# STM32WB09 register map
File version: 1.0
CPU: CM0+ r0p0, little endian, MPU, no FPU, 2 interrupt priority bits
Registers are 32-bit, read-write, reset 0x0 unless marked. A register's access mark holds for its fields unless they carry their own. Offsets are from the block's base; [hi:lo] are bit positions.

## RADIO
Base 0x60001500
0x00 AA0_DIG_USR reset 0xD6
  [7:0] AA_7_0 — Least significant byte of the Bluetooth LE Access Address code
0x04 AA1_DIG_USR reset 0xBE
  [7:0] AA_15_8 — Next byte of the Bluetooth LE Access Address code.
0x08 AA2_DIG_USR reset 0x89
  [7:0] AA_23_16 — Next byte of the Bluetooth LE Access Address code
0x0C AA3_DIG_USR reset 0x8E
  [7:0] AA_31_24 — Most significant byte of the Bluetooth LE Access Address code.
0x10 DEM_MOD_DIG_USR reset 0x26
  [7:1] CHANNEL_NUM — Index for internal lock up table in which the synthesizer setup is contained.
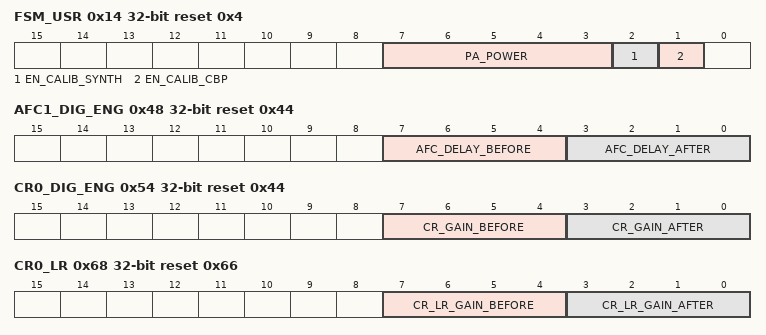
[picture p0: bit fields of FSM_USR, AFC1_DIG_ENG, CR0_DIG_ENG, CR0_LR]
0x14 FSM_USR reset 0x4 — RADIO_FSM_USR register
  [7:3] PA_POWER — PA Power coefficient.
  [2] EN_CALIB_SYNTH — SYNTH calibration enable bit.
  [1] EN_CALIB_CBP — CBP calibration enable bit.
0x18 PHYCTRL_DIG_USR
  [2:0] RXTXPHY — RXTXPHY selection.
0x48 AFC1_DIG_ENG reset 0x44
  [7:4] AFC_DELAY_BEFORE — Set the decay factor of the AFC loop before Access Address detection
  [3:0] AFC_DELAY_AFTER — Set the decay factor of the AFC loop after Access Address detection
0x54 CR0_DIG_ENG reset 0x44
  [7:4] CR_GAIN_BEFORE — Set the gain of the clock recovery loop before Access Address detection to the value
  [3:0] CR_GAIN_AFTER — Set the gain of the clock recovery loop before Access Address detection to the value
0x68 CR0_LR reset 0x66
  [7:4] CR_LR_GAIN_BEFORE — Set the gain of the clock recovery loop before Access Address detection to the value 2^(-CR_LR_GAIN_ BEFORE) when the coded PHY is in use
  [3:0] CR_LR_GAIN_AFTER — Set the gain of the clock recovery loop after Access Address detection to the value 2^(-CR_LR_GAIN_ AFTER) when the coded PHY is in use
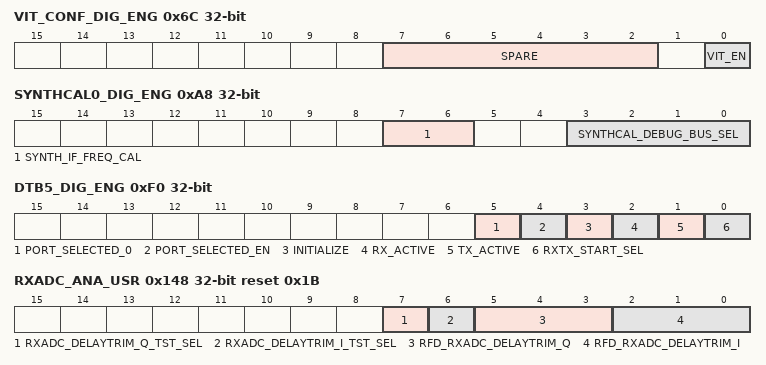
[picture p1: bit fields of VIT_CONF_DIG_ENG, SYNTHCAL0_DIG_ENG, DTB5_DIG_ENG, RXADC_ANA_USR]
0x6C VIT_CONF_DIG_ENG
  [7:2] SPARE
  [0] VIT_EN — Viterbi enable
0x84 LR_PD_THR_DIG_ENG reset 0x50
  [7:0] LR_PD_THR — preamble detect threshold value
0x88 LR_RSSI_THR_DIG_ENG reset 0x1B
  [7:0] LR_RSSI_THR — RSSI or peak threshold value
0x8C LR_AAC_THR_DIG_ENG reset 0x38
  [7:0] LR_AAC_THR — address coded correlation threshold
0xA8 SYNTHCAL0_DIG_ENG
  [7:6] SYNTH_IF_FREQ_CAL — Define the frequency applied on the PLL during calibration phase
  [3:0] SYNTHCAL_DEBUG_BUS_SEL — for Debug purpose
0xF0 DTB5_DIG_ENG
  [5] PORT_SELECTED_0 — force port_selected[0] signal
  [4] PORT_SELECTED_EN — enable port selection
  [3] INITIALIZE — Force INITIALIZE signal (emulate a token request of the IP_BLE)
  [2] RX_ACTIVE — Force RX_ACTIVE signal
  [1] TX_ACTIVE — Force TX_ACTIVE signal
  [0] RXTX_START_SEL — enable the possibility to control some signals by the other register bits instead of system design:
0x148 RXADC_ANA_USR reset 0x1B
  [7] RXADC_DELAYTRIM_Q_TST_SEL — Enable the SW overload on RXADX delay trimming
  [6] RXADC_DELAYTRIM_I_TST_SEL — Enable the SW overload on RXADX delay trimming
  [5:3] RFD_RXADC_DELAYTRIM_Q — ADC loop delay control bits for Q channel to apply when SW overload is enabled
  [2:0] RFD_RXADC_DELAYTRIM_I — ADC loop delay control bits for I channel to apply when SW overload is enabled
0x154 LDO_ANA_ENG
  [0] RFD_RF_REG_BYPASS — RF_REG Bypass mode:
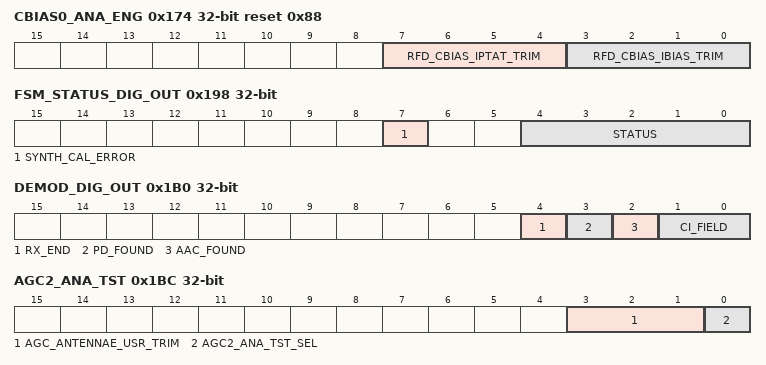
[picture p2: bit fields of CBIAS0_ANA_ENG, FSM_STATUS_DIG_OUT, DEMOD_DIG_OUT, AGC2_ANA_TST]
0x174 CBIAS0_ANA_ENG reset 0x88
  [7:4] RFD_CBIAS_IPTAT_TRIM — overloaded value for cbias current trimming (when CBIAS0_TRIM_TST_SEL = 1)
  [3:0] RFD_CBIAS_IBIAS_TRIM — overloaded value for cbias current trimming (when CBIAS0_TRIM_TST_SEL = 1)
0x178 CBIAS1_ANA_ENG
  [7] CBIAS0_TRIM_TST_SEL — When set, RFD_CBIAS_(IPTAT/IBIAS)_TRIM are used instead of HW trimmings
0x180 SYNTHCAL0_DIG_OUT ro
  [6:0] VCO_CALAMP_OUT_6_0 — VCO CALAMP value
0x184 SYNTHCAL1_DIG_OUT ro reset 0x1
  [3:0] VCO_CALAMP_OUT_10_7 — VCO CALAMP value
0x188 SYNTHCAL2_DIG_OUT ro reset 0x40
  [6:0] VCO_CALFREQ_OUT — VCO CALFREQ value
0x18C SYNTHCAL3_DIG_OUT ro
  [7:0] SYNTHCAL_DEBUG_BUS — Calibration debug bus.
0x190 SYNTHCAL4_DIG_OUT ro reset 0x18
  [5:0] MOD_REF_DAC_WORD_OUT — Calibration word
0x194 SYNTHCAL5_DIG_OUT ro reset 0x7
  [3:0] CBP_CALIB_WORD — CBP Calibration word
0x198 FSM_STATUS_DIG_OUT ro
  [7] SYNTH_CAL_ERROR — PLL calibration error
  [4:0] STATUS — RF FSM state:
0x1A4 RSSI0_DIG_OUT ro reset 0x8
  [7:0] RSSI_MEAS_OUT_7_0 — Measure of the received signal strength.
0x1A8 RSSI1_DIG_OUT ro reset 0x8
  [7:0] RSSI_MEAS_OUT_15_8 — Measure of the received signal strength
0x1AC AGC_DIG_OUT ro
  [3:0] AGC_ATT_OUT — AGC attenuation value
0x1B0 DEMOD_DIG_OUT ro
  [4] RX_END, [3] PD_FOUND, [2] AAC_FOUND, [1:0] CI_FIELD
0x1BC AGC2_ANA_TST
  [3:1] AGC_ANTENNAE_USR_TRIM — the AGC antenna trimming value ( when AGC2_ANA_TST_SEL = 1)
  [0] AGC2_ANA_TST_SEL — Selection:
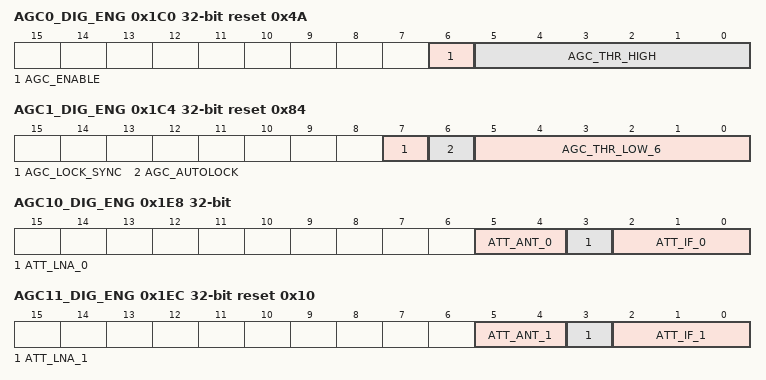
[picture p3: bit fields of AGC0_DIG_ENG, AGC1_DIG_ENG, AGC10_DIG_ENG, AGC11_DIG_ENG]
0x1C0 AGC0_DIG_ENG reset 0x4A
  [6] AGC_ENABLE — Enable AGC
  [5:0] AGC_THR_HIGH — High AGC threshold
0x1C4 AGC1_DIG_ENG reset 0x84
  [7] AGC_LOCK_SYNC — AGC locks when Access Address is detected (recommended)
  [6] AGC_AUTOLOCK — AGC locks when level is steady between high threshold and lock threshold
  [5:0] AGC_THR_LOW_6 — Low threshold for 6dB steps
0x1E8 AGC10_DIG_ENG
  [5:4] ATT_ANT_0 — Attenuation at Antenna Level for the AGC step 0:
  [3] ATT_LNA_0 — Attenuation at LNA Level for the AGC step 0:
  [2:0] ATT_IF_0 — Attenuation at IF Level for the AGC step 0:
0x1EC AGC11_DIG_ENG reset 0x10
  [5:4] ATT_ANT_1 — Attenuation at Antenna Level for the AGC step 1
  [3] ATT_LNA_1 — Attenuation at LNA Level for the AGC step 1
  [2:0] ATT_IF_1 — Attenuation at IF Level for the AGC step 1
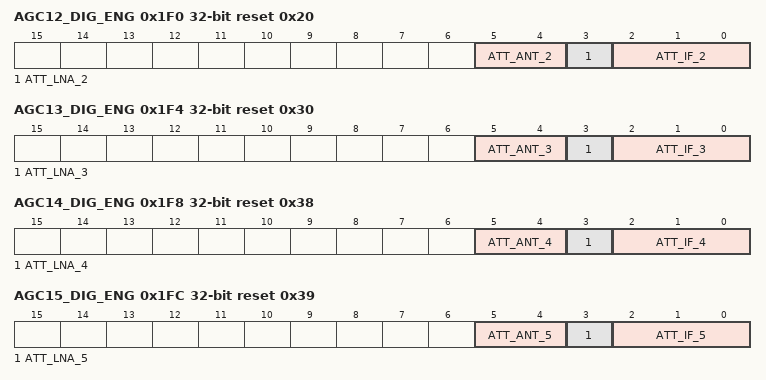
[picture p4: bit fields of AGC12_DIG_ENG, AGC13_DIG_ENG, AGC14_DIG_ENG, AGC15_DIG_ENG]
0x1F0 AGC12_DIG_ENG reset 0x20
  [5:4] ATT_ANT_2 — Attenuation at Antenna Level for the AGC step 2
  [3] ATT_LNA_2 — Attenuation at LNA Level for the AGC step 2
  [2:0] ATT_IF_2 — Attenuation at IF Level for the AGC step 2
0x1F4 AGC13_DIG_ENG reset 0x30
  [5:4] ATT_ANT_3 — Attenuation at Antenna Level for the AGC step 3
  [3] ATT_LNA_3 — Attenuation at LNA Level for the AGC step 3
  [2:0] ATT_IF_3 — Attenuation at IF Level for the AGC step 3
0x1F8 AGC14_DIG_ENG reset 0x38
  [5:4] ATT_ANT_4 — Attenuation at Antenna Level for the AGC step 4
  [3] ATT_LNA_4 — Attenuation at LNA Level for the AGC step 4
  [2:0] ATT_IF_4 — Attenuation at IF Level for the AGC step 4
0x1FC AGC15_DIG_ENG reset 0x39
  [5:4] ATT_ANT_5 — Attenuation at Antenna Level for the AGC step 5
  [3] ATT_LNA_5 — Attenuation at LNA Level for the AGC step 5
  [2:0] ATT_IF_5 — Attenuation at IF Level for the AGC step 5
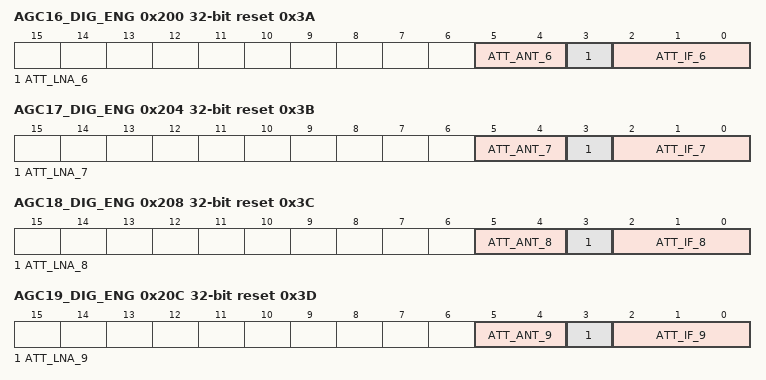
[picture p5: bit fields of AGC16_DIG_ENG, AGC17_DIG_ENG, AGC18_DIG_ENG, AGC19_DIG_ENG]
0x200 AGC16_DIG_ENG reset 0x3A
  [5:4] ATT_ANT_6 — Attenuation at Antenna Level for the AGC step 6
  [3] ATT_LNA_6 — Attenuation at LNA Level for the AGC step 6
  [2:0] ATT_IF_6 — Attenuation at IF Level for the AGC step 6
0x204 AGC17_DIG_ENG reset 0x3B
  [5:4] ATT_ANT_7 — Attenuation at Antenna Level for the AGC step 7
  [3] ATT_LNA_7 — Attenuation at LNA Level for the AGC step 7
  [2:0] ATT_IF_7 — Attenuation at IF Level for the AGC step 7
0x208 AGC18_DIG_ENG reset 0x3C
  [5:4] ATT_ANT_8 — Attenuation at Antenna Level for the AGC step 8
  [3] ATT_LNA_8 — Attenuation at LNA Level for the AGC step 8
  [2:0] ATT_IF_8 — Attenuation at IF Level for the AGC step 8
0x20C AGC19_DIG_ENG reset 0x3D
  [5:4] ATT_ANT_9 — Attenuation at Antenna Level for the AGC step 9
  [3] ATT_LNA_9 — Attenuation at LNA Level for the AGC step 9
  [2:0] ATT_IF_9 — Attenuation at IF Level for the AGC step 9
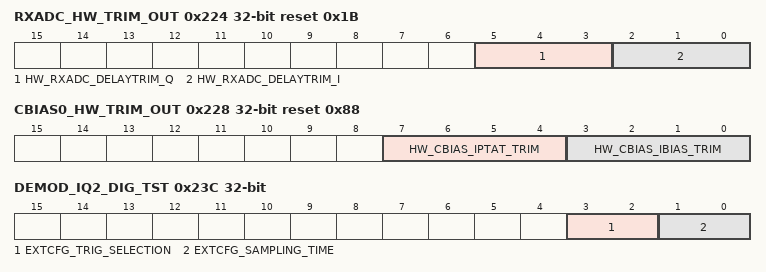
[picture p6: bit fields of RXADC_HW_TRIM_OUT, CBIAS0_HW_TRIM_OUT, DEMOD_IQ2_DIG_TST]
0x224 RXADC_HW_TRIM_OUT ro reset 0x1B
  [5:3] HW_RXADC_DELAYTRIM_Q — control bits of the RX ADC loop delay for Q channel (provided by the HW trimming, automatically loaded on POR).
  [2:0] HW_RXADC_DELAYTRIM_I — control bits of the RX ADC loop delay for I channel (provided by the HW trimming, automatically loaded on POR).
0x228 CBIAS0_HW_TRIM_OUT ro reset 0x88
  [7:4] HW_CBIAS_IPTAT_TRIM — CBIAS current (provided by the HW trimming, automatically loaded on POR).
  [3:0] HW_CBIAS_IBIAS_TRIM — CBIAS current (provided by the HW trimming, automatically loaded on POR).
0x230 AGC_HW_TRIM_OUT ro reset 0x6
  [3:1] HW_AGC_ANTENNAE_TRIM — AGC trim value (provided by the HW trimming, automatically loaded on POR).
0x23C DEMOD_IQ2_DIG_TST
  [3:2] EXTCFG_TRIG_SELECTION — Defines the trigger/anchor point of the IQ sampling, when extended configuration is enabled:
  [1:0] EXTCFG_SAMPLING_TIME — Defines the sampling time, when extended configuration is enabled:
0x240 ANTSW0_DIG_USR reset 0x1C
  [6:0] RX_TIME_TO_SAMPLE — specifies the exact timing of the first I/Q sampling in the reference period.
0x244 ANTSW1_DIG_USR reset 0xB
  [5:0] RX_TIME_TO_SWITCH — specifies the exact timing of the antenna switching at receiver level (in AoA).
0x248 ANTSW2_DIG_USR reset 0x29
  [6:0] TX_TIME_TO_SWITCH — specifies the exact timing of the antenna switching during transmission at LE_1M baud rate (in AoD).
0x24C ANTSW3_DIG_USR reset 0x23
  [6:0] TX_TIME_TO_SWITCH_2M — specifies the exact timing of the antenna switching during transmission at LE_2M baud rate (in AoD).
